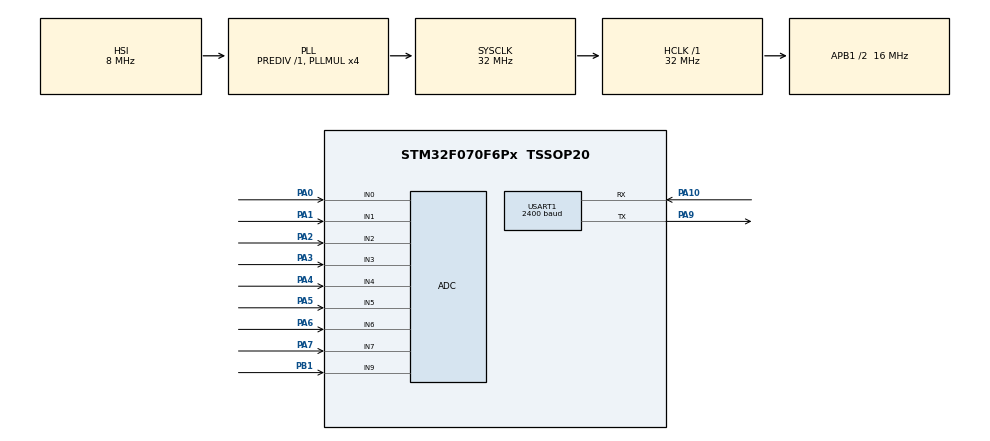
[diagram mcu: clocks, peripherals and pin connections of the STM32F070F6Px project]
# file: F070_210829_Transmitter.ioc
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Mcu.Family=STM32F0
Dma.USART1_TX.1.Instance=DMA1_Channel2
PA6.Mode=IN6
PA7.Mode=IN7
PA10.Mode=Asynchronous
Dma.ADC.0.Mode=DMA_CIRCULAR
TIM14.AutoReloadPreload=TIM_AUTORELOAD_PRELOAD_ENABLE
Dma.USART1_TX.1.MemInc=DMA_MINC_ENABLE
USART1.BaudRate=2400
USART1.WordLength=WORDLENGTH_8B
Dma.ADC.0.Priority=DMA_PRIORITY_HIGH
RCC.APB1CLKDivider=RCC_HCLK_DIV2
RCC.SYSCLKSource=RCC_SYSCLKSOURCE_PLLCLK
ProjectManager.StackSize=0x400
Dma.ADC.0.PeriphDataAlignment=DMA_PDATAALIGN_HALFWORD
PA3.Mode=IN3
PA13.Signal=SYS_SWDIO
TIM1.AutoReloadPreload=TIM_AUTORELOAD_PRELOAD_ENABLE
PA9.Mode=Asynchronous
TIM1.Prescaler=1000-1
USART1.StopBits=STOPBITS_1
PA4.Mode=IN4
ProjectManager.TargetToolchain=STM32CubeIDE
Dma.ADC.0.PeriphInc=DMA_PINC_DISABLE
RCC.HCLKFreq_Value=32000000
PA9.Signal=USART1_TX
USART1.Parity=PARITY_EVEN
PA1.Signal=ADC_IN1
RCC.AHBFreq_Value=32000000
Dma.ADC.0.Direction=DMA_PERIPH_TO_MEMORY
ADC.SamplingTime=ADC_SAMPLETIME_239CYCLES_5
PA5.Signal=ADC_IN5
ADC.DMAContinuousRequests=ENABLE
Dma.USART1_TX.1.MemDataAlignment=DMA_MDATAALIGN_BYTE
board=custom
TIM14.Period=4800-1
RCC.PLLMUL=RCC_PLL_MUL4
TIM1.TIM_MasterOutputTrigger=TIM_TRGO_UPDATE
PA1.Mode=IN1
USART1.Mode=MODE_TX
PA14.Mode=Serial_Wire
USART1.OverrunDisableParam=ADVFEATURE_OVERRUN_DISABLE
PA0.Mode=IN0
PA13.Mode=Serial_Wire
Mcu.Name=STM32F070F6Px
VP_TIM1_VS_ClockSourceINT.Mode=Internal
Dma.USART1_TX.1.PeriphDataAlignment=DMA_PDATAALIGN_BYTE
TIM14.Prescaler=1000-1
PA2.Signal=ADC_IN2
PA0.Signal=ADC_IN0
ADC.Overrun=ADC_OVR_DATA_OVERWRITTEN
Dma.ADC.0.MemInc=DMA_MINC_ENABLE
PA4.Signal=ADC_IN4
RCC.SYSCLKFreq_VALUE=32000000
Mcu.Package=TSSOP20
PA6.Signal=ADC_IN6
PB1.Signal=ADC_IN9
Dma.USART1_TX.1.Mode=DMA_NORMAL
USART1.VirtualMode=VM_ASYNC
Dma.ADC.0.Instance=DMA1_Channel1
USART1.MSBFirstParam=ADVFEATURE_MSBFIRST_DISABLE
PA10.Signal=USART1_RX
PA14.Signal=SYS_SWCLK
ProjectManager.HeapSize=0x200
Dma.USART1_TX.1.PeriphInc=DMA_PINC_DISABLE
PB1.Mode=IN9
USART1.DMADisableonRxErrorParam=ADVFEATURE_DMA_DISABLEONRXERROR
Dma.ADC.0.MemDataAlignment=DMA_MDATAALIGN_HALFWORD
NVIC.DMA1_Channel2_3_IRQn=true\:0\:0\:false\:false\:true\:false\:true
Dma.Request1=USART1_TX
RCC.APB1TimFreq_Value=32000000
PA2.Mode=IN2
Dma.USART1_TX.1.Priority=DMA_PRIORITY_LOW
TIM1.Period=4800-1
VP_TIM14_VS_ClockSourceINT.Mode=Enable_Timer
NVIC.DMA1_Channel1_IRQn=true\:0\:0\:false\:false\:true\:false\:true
Dma.Request0=ADC
RCC.APB1Freq_Value=16000000
VP_CRC_VS_CRC.Mode=CRC_Activate
ADC.ContinuousConvMode=DISABLE
ADC.ExternalTrigConv=ADC_EXTERNALTRIGCONV_T1_TRGO
PA3.Signal=ADC_IN3
PA5.Mode=IN5
PA7.Signal=ADC_IN7
Dma.USART1_TX.1.Direction=DMA_MEMORY_TO_PERIPH

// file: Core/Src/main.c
/* USER CODE BEGIN Header */
/**
  ******************************************************************************
  * @file           : main.c
  * @brief          : Main program body
  ******************************************************************************
  * @attention
  *
  * <h2><center>&copy; Copyright (c) 2021 STMicroelectronics.
  * All rights reserved.</center></h2>
  *
  * This software component is licensed by ST under BSD 3-Clause license,
  * the "License"; You may not use this file except in compliance with the
  * License. You may obtain a copy of the License at:
  *                        opensource.org/licenses/BSD-3-Clause
  *
  ******************************************************************************
  */
/* USER CODE END Header */
#include "main.h"

/* USER CODE BEGIN Includes */
#include "stdio.h"
#include "adc.h"
#include "init.h"
#include "processing.h"
#include "transmission.h"

/* USER CODE END Includes */

ADC_HandleTypeDef hadc;
DMA_HandleTypeDef hdma_adc;

CRC_HandleTypeDef hcrc;

TIM_HandleTypeDef htim1;
TIM_HandleTypeDef htim14;

UART_HandleTypeDef huart1;
DMA_HandleTypeDef hdma_usart1_tx;

void SystemClock_Config(void);
static void MX_GPIO_Init(void);
static void MX_DMA_Init(void);
static void MX_ADC_Init(void);
static void MX_TIM1_Init(void);
static void MX_USART1_UART_Init(void);
static void MX_CRC_Init(void);
static void MX_TIM14_Init(void);

int main(void)
{

  /* MCU Configuration--------------------------------------------------------*/

  /* Reset of all peripherals, Initializes the Flash interface and the Systick. */
  HAL_Init();

  /* Configure the system clock */
  SystemClock_Config();

  /* Initialize all configured peripherals */
  MX_GPIO_Init();
  MX_DMA_Init();
  MX_ADC_Init();
  MX_TIM1_Init();
  MX_USART1_UART_Init();
  MX_CRC_Init();
  MX_TIM14_Init();
  /* USER CODE BEGIN 2 */
  HAL_TIM_Base_Start(&htim1);
  HAL_TIM_Base_Start(&htim14);
  HAL_ADC_Start_DMA(&hadc, (uint32_t *)adcBuffer, buffLength);

  /* USER CODE END 2 */

  /* Infinite loop */
  while (1)
  {

  }
}

void SystemClock_Config(void)
{
  RCC_OscInitTypeDef RCC_OscInitStruct = {0};
  RCC_ClkInitTypeDef RCC_ClkInitStruct = {0};
  RCC_PeriphCLKInitTypeDef PeriphClkInit = {0};

  /** Initializes the RCC Oscillators according to the specified parameters
  * in the RCC_OscInitTypeDef structure.
  */
  RCC_OscInitStruct.OscillatorType = RCC_OSCILLATORTYPE_HSI|RCC_OSCILLATORTYPE_HSI14;
  RCC_OscInitStruct.HSIState = RCC_HSI_ON;
  RCC_OscInitStruct.HSI14State = RCC_HSI14_ON;
  RCC_OscInitStruct.HSICalibrationValue = RCC_HSICALIBRATION_DEFAULT;
  RCC_OscInitStruct.HSI14CalibrationValue = 16;
  RCC_OscInitStruct.PLL.PLLState = RCC_PLL_ON;
  RCC_OscInitStruct.PLL.PLLSource = RCC_PLLSOURCE_HSI;
  RCC_OscInitStruct.PLL.PLLMUL = RCC_PLL_MUL4;
  RCC_OscInitStruct.PLL.PREDIV = RCC_PREDIV_DIV1;
  if (HAL_RCC_OscConfig(&RCC_OscInitStruct) != HAL_OK)
  {
    Error_Handler();
  }
  /** Initializes the CPU, AHB and APB buses clocks
  */
  RCC_ClkInitStruct.ClockType = RCC_CLOCKTYPE_HCLK|RCC_CLOCKTYPE_SYSCLK
                              |RCC_CLOCKTYPE_PCLK1;
  RCC_ClkInitStruct.SYSCLKSource = RCC_SYSCLKSOURCE_PLLCLK;
  RCC_ClkInitStruct.AHBCLKDivider = RCC_SYSCLK_DIV1;
  RCC_ClkInitStruct.APB1CLKDivider = RCC_HCLK_DIV2;

  if (HAL_RCC_ClockConfig(&RCC_ClkInitStruct, FLASH_LATENCY_1) != HAL_OK)
  {
    Error_Handler();
  }
  PeriphClkInit.PeriphClockSelection = RCC_PERIPHCLK_USART1;
  PeriphClkInit.Usart1ClockSelection = RCC_USART1CLKSOURCE_PCLK1;
  if (HAL_RCCEx_PeriphCLKConfig(&PeriphClkInit) != HAL_OK)
  {
    Error_Handler();
  }
}

static void MX_ADC_Init(void)
{

  ADC_ChannelConfTypeDef sConfig = {0};

  /** Configure the global features of the ADC (Clock, Resolution, Data Alignment and number of conversion)
  */
  hadc.Instance = ADC1;
  hadc.Init.ClockPrescaler = ADC_CLOCK_ASYNC_DIV1;
  hadc.Init.Resolution = ADC_RESOLUTION_12B;
  hadc.Init.DataAlign = ADC_DATAALIGN_RIGHT;
  hadc.Init.ScanConvMode = ADC_SCAN_DIRECTION_FORWARD;
  hadc.Init.EOCSelection = ADC_EOC_SINGLE_CONV;
  hadc.Init.LowPowerAutoWait = DISABLE;
  hadc.Init.LowPowerAutoPowerOff = DISABLE;
  hadc.Init.ContinuousConvMode = DISABLE;
  hadc.Init.DiscontinuousConvMode = DISABLE;
  hadc.Init.ExternalTrigConv = ADC_EXTERNALTRIGCONV_T1_TRGO;
  hadc.Init.ExternalTrigConvEdge = ADC_EXTERNALTRIGCONVEDGE_RISING;
  hadc.Init.DMAContinuousRequests = ENABLE;
  hadc.Init.Overrun = ADC_OVR_DATA_OVERWRITTEN;
  if (HAL_ADC_Init(&hadc) != HAL_OK)
  {
    Error_Handler();
  }
  /** Configure for the selected ADC regular channel to be converted.
  */
  sConfig.Channel = ADC_CHANNEL_0;
  sConfig.Rank = ADC_RANK_CHANNEL_NUMBER;
  sConfig.SamplingTime = ADC_SAMPLETIME_239CYCLES_5;
  if (HAL_ADC_ConfigChannel(&hadc, &sConfig) != HAL_OK)
  {
    Error_Handler();
  }
  /** Configure for the selected ADC regular channel to be converted.
  */
  sConfig.Channel = ADC_CHANNEL_1;
  if (HAL_ADC_ConfigChannel(&hadc, &sConfig) != HAL_OK)
  {
    Error_Handler();
  }
  /** Configure for the selected ADC regular channel to be converted.
  */
  sConfig.Channel = ADC_CHANNEL_2;
  if (HAL_ADC_ConfigChannel(&hadc, &sConfig) != HAL_OK)
  {
    Error_Handler();
  }
  /** Configure for the selected ADC regular channel to be converted.
  */
  sConfig.Channel = ADC_CHANNEL_3;
  if (HAL_ADC_ConfigChannel(&hadc, &sConfig) != HAL_OK)
  {
    Error_Handler();
  }
  /** Configure for the selected ADC regular channel to be converted.
  */
  sConfig.Channel = ADC_CHANNEL_4;
  if (HAL_ADC_ConfigChannel(&hadc, &sConfig) != HAL_OK)
  {
    Error_Handler();
  }
  /** Configure for the selected ADC regular channel to be converted.
  */
  sConfig.Channel = ADC_CHANNEL_5;
  if (HAL_ADC_ConfigChannel(&hadc, &sConfig) != HAL_OK)
  {
    Error_Handler();
  }
  /** Configure for the selected ADC regular channel to be converted.
  */
  sConfig.Channel = ADC_CHANNEL_6;
  if (HAL_ADC_ConfigChannel(&hadc, &sConfig) != HAL_OK)
  {
    Error_Handler();
  }
  /** Configure for the selected ADC regular channel to be converted.
  */
  sConfig.Channel = ADC_CHANNEL_7;
  if (HAL_ADC_ConfigChannel(&hadc, &sConfig) != HAL_OK)
  {
    Error_Handler();
  }
  /** Configure for the selected ADC regular channel to be converted.
  */
  sConfig.Channel = ADC_CHANNEL_9;
  if (HAL_ADC_ConfigChannel(&hadc, &sConfig) != HAL_OK)
  {
    Error_Handler();
  }

}

static void MX_CRC_Init(void)
{

  hcrc.Instance = CRC;
  hcrc.Init.DefaultInitValueUse = DEFAULT_INIT_VALUE_ENABLE;
  hcrc.Init.InputDataInversionMode = CRC_INPUTDATA_INVERSION_NONE;
  hcrc.Init.OutputDataInversionMode = CRC_OUTPUTDATA_INVERSION_DISABLE;
  hcrc.InputDataFormat = CRC_INPUTDATA_FORMAT_BYTES;
  if (HAL_CRC_Init(&hcrc) != HAL_OK)
  {
    Error_Handler();
  }

}

static void MX_TIM1_Init(void)
{

  TIM_ClockConfigTypeDef sClockSourceConfig = {0};
  TIM_MasterConfigTypeDef sMasterConfig = {0};

  htim1.Instance = TIM1;
  htim1.Init.Prescaler = 1000-1;
  htim1.Init.CounterMode = TIM_COUNTERMODE_UP;
  htim1.Init.Period = 4800-1;
  htim1.Init.ClockDivision = TIM_CLOCKDIVISION_DIV1;
  htim1.Init.RepetitionCounter = 0;
  htim1.Init.AutoReloadPreload = TIM_AUTORELOAD_PRELOAD_ENABLE;
  if (HAL_TIM_Base_Init(&htim1) != HAL_OK)
  {
    Error_Handler();
  }
  sClockSourceConfig.ClockSource = TIM_CLOCKSOURCE_INTERNAL;
  if (HAL_TIM_ConfigClockSource(&htim1, &sClockSourceConfig) != HAL_OK)
  {
    Error_Handler();
  }
  sMasterConfig.MasterOutputTrigger = TIM_TRGO_UPDATE;
  sMasterConfig.MasterSlaveMode = TIM_MASTERSLAVEMODE_DISABLE;
  if (HAL_TIMEx_MasterConfigSynchronization(&htim1, &sMasterConfig) != HAL_OK)
  {
    Error_Handler();
  }

}

static void MX_TIM14_Init(void)
{

  htim14.Instance = TIM14;
  htim14.Init.Prescaler = 1000-1;
  htim14.Init.CounterMode = TIM_COUNTERMODE_UP;
  htim14.Init.Period = 4800-1;
  htim14.Init.ClockDivision = TIM_CLOCKDIVISION_DIV1;
  htim14.Init.AutoReloadPreload = TIM_AUTORELOAD_PRELOAD_ENABLE;
  if (HAL_TIM_Base_Init(&htim14) != HAL_OK)
  {
    Error_Handler();
  }

}

static void MX_USART1_UART_Init(void)
{

  huart1.Instance = USART1;
  huart1.Init.BaudRate = 2400;
  huart1.Init.WordLength = UART_WORDLENGTH_8B;
  huart1.Init.StopBits = UART_STOPBITS_1;
  huart1.Init.Parity = UART_PARITY_EVEN;
  huart1.Init.Mode = UART_MODE_TX;
  huart1.Init.HwFlowCtl = UART_HWCONTROL_NONE;
  huart1.Init.OverSampling = UART_OVERSAMPLING_16;
  huart1.Init.OneBitSampling = UART_ONE_BIT_SAMPLE_DISABLE;
  huart1.AdvancedInit.AdvFeatureInit = UART_ADVFEATURE_RXOVERRUNDISABLE_INIT|UART_ADVFEATURE_DMADISABLEONERROR_INIT;
  huart1.AdvancedInit.OverrunDisable = UART_ADVFEATURE_OVERRUN_DISABLE;
  huart1.AdvancedInit.DMADisableonRxError = UART_ADVFEATURE_DMA_DISABLEONRXERROR;
  if (HAL_UART_Init(&huart1) != HAL_OK)
  {
    Error_Handler();
  }

}

static void MX_DMA_Init(void)
{

  /* DMA controller clock enable */
  __HAL_RCC_DMA1_CLK_ENABLE();

  /* DMA interrupt init */
  /* DMA1_Channel1_IRQn interrupt configuration */
  HAL_NVIC_SetPriority(DMA1_Channel1_IRQn, 0, 0);
  HAL_NVIC_EnableIRQ(DMA1_Channel1_IRQn);
  /* DMA1_Channel2_3_IRQn interrupt configuration */
  HAL_NVIC_SetPriority(DMA1_Channel2_3_IRQn, 0, 0);
  HAL_NVIC_EnableIRQ(DMA1_Channel2_3_IRQn);

}

static void MX_GPIO_Init(void)
{

  /* GPIO Ports Clock Enable */
  __HAL_RCC_GPIOA_CLK_ENABLE();
  __HAL_RCC_GPIOB_CLK_ENABLE();

}

void Error_Handler(void)
{
  __disable_irq();
  while (1)
  {
  }
}

/************************ (C) COPYRIGHT STMicroelectronics *****END OF FILE****/
